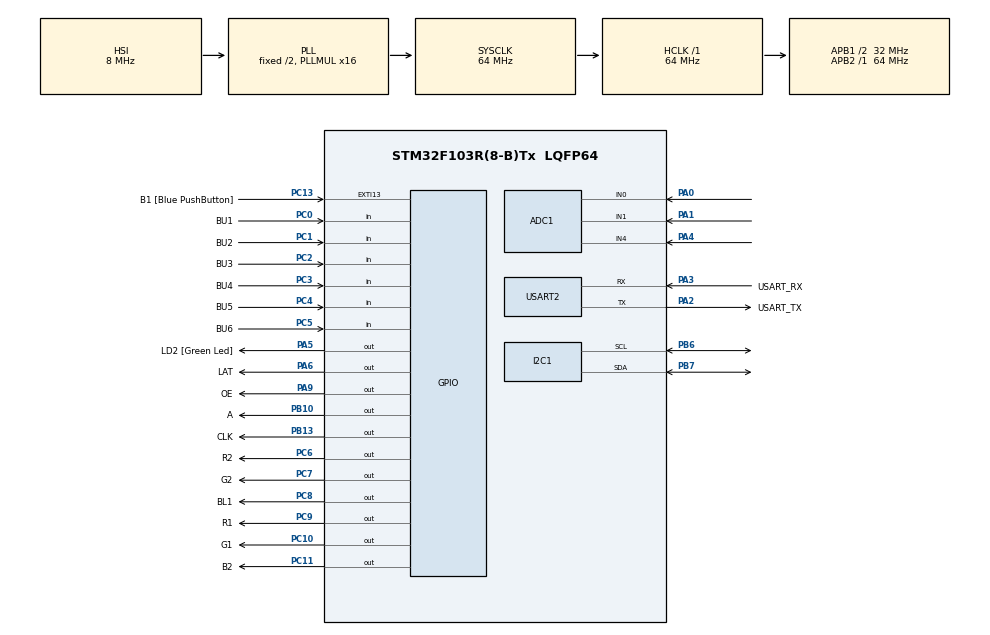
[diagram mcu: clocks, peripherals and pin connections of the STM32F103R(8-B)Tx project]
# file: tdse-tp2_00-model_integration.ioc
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ADC1.Channel-0\#ChannelRegularConversion=ADC_CHANNEL_0
ADC1.Channel-1\#ChannelRegularConversion=ADC_CHANNEL_1
ADC1.Channel-2\#ChannelRegularConversion=ADC_CHANNEL_4
ADC1.ContinuousConvMode=ENABLE
ADC1.NbrOfConversion=3
ADC1.NbrOfConversionFlag=1
ADC1.Rank-0\#ChannelRegularConversion=1
ADC1.Rank-1\#ChannelRegularConversion=2
ADC1.Rank-2\#ChannelRegularConversion=3
ADC1.SamplingTime-0\#ChannelRegularConversion=ADC_SAMPLETIME_239CYCLES_5
ADC1.SamplingTime-1\#ChannelRegularConversion=ADC_SAMPLETIME_239CYCLES_5
ADC1.SamplingTime-2\#ChannelRegularConversion=ADC_SAMPLETIME_239CYCLES_5
ADC1.master=1
Dma.ADC1.0.Direction=DMA_PERIPH_TO_MEMORY
Dma.ADC1.0.Instance=DMA1_Channel1
Dma.ADC1.0.MemDataAlignment=DMA_MDATAALIGN_HALFWORD
Dma.ADC1.0.MemInc=DMA_MINC_ENABLE
Dma.ADC1.0.Mode=DMA_CIRCULAR
Dma.ADC1.0.PeriphDataAlignment=DMA_PDATAALIGN_HALFWORD
Dma.ADC1.0.PeriphInc=DMA_PINC_DISABLE
Dma.ADC1.0.Priority=DMA_PRIORITY_LOW
Dma.Request0=ADC1
Mcu.Family=STM32F1
Mcu.Name=STM32F103R(8-B)Tx
Mcu.Package=LQFP64
NVIC.ADC1_2_IRQn=true\:0\:0\:false\:false\:true\:true\:true\:true
NVIC.DMA1_Channel1_IRQn=true\:0\:0\:false\:false\:true\:false\:true\:true
NVIC.EXTI15_10_IRQn=true\:0\:0\:false\:false\:true\:true\:true\:true
NVIC.PriorityGroup=NVIC_PRIORITYGROUP_4
PA0-WKUP.Signal=ADCx_IN0
PA1.Signal=ADCx_IN1
PA13.GPIO_Label=TMS
PA13.Mode=Serial_Wire
PA13.Signal=SYS_JTMS-SWDIO
PA14.GPIO_Label=TCK
PA14.Mode=Serial_Wire
PA14.Signal=SYS_JTCK-SWCLK
PA2.GPIO_Label=USART_TX
PA2.GPIO_Mode=GPIO_MODE_AF_PP
PA2.GPIO_PuPd=GPIO_NOPULL
PA2.GPIO_Speed=GPIO_SPEED_FREQ_LOW
PA2.Mode=Asynchronous
PA2.Signal=USART2_TX
PA3.GPIO_Label=USART_RX
PA3.GPIO_Mode=GPIO_MODE_AF_PP
PA3.GPIO_PuPd=GPIO_NOPULL
PA3.GPIO_Speed=GPIO_SPEED_FREQ_LOW
PA3.Mode=Asynchronous
PA3.Signal=USART2_RX
PA4.Signal=ADCx_IN4
PA5.GPIO_Label=LD2 [Green Led]
PA5.GPIO_ModeDefaultOutputPP=GPIO_MODE_OUTPUT_PP
PA5.GPIO_PuPd=GPIO_NOPULL
PA5.GPIO_Speed=GPIO_SPEED_FREQ_LOW
PA5.Signal=GPIO_Output
PA6.GPIO_Label=LAT
PA6.GPIO_Speed=GPIO_SPEED_FREQ_HIGH
PA6.Signal=GPIO_Output
PA9.GPIO_Label=OE
PA9.GPIO_Speed=GPIO_SPEED_FREQ_HIGH
PA9.Signal=GPIO_Output
PB10.GPIO_Label=A
PB10.GPIO_Speed=GPIO_SPEED_FREQ_HIGH
PB10.Signal=GPIO_Output
PB13.GPIO_Label=CLK
PB13.GPIO_Speed=GPIO_SPEED_FREQ_HIGH
PB13.Signal=GPIO_Output
PB3.GPIO_Label=SWO
PB3.Signal=SYS_JTDO-TRACESWO
PB6.Mode=I2C
PB6.Signal=I2C1_SCL
PB7.Mode=I2C
PB7.Signal=I2C1_SDA
PC0.GPIO_Label=BU1
PC0.GPIO_PuPd=GPIO_PULLUP
PC0.Signal=GPIO_Input
PC1.GPIO_Label=BU2
PC1.GPIO_PuPd=GPIO_PULLUP
PC1.Signal=GPIO_Input
PC10.GPIO_Label=G1
PC10.GPIO_Speed=GPIO_SPEED_FREQ_HIGH
PC10.Signal=GPIO_Output
PC11.GPIO_Label=B2
PC11.GPIO_Speed=GPIO_SPEED_FREQ_HIGH
PC11.Signal=GPIO_Output
PC13-TAMPER-RTC.GPIO_Label=B1 [Blue PushButton]
PC13-TAMPER-RTC.GPIO_PuPd=GPIO_NOPULL
PC13-TAMPER-RTC.Signal=GPXTI13
PC14-OSC32_IN.Mode=LSE-External-Oscillator
PC14-OSC32_IN.Signal=RCC_OSC32_IN
PC15-OSC32_OUT.Mode=LSE-External-Oscillator
PC15-OSC32_OUT.Signal=RCC_OSC32_OUT
PC2.GPIO_Label=BU3
PC2.GPIO_PuPd=GPIO_PULLUP
PC2.Signal=GPIO_Input
PC3.GPIO_Label=BU4
PC3.GPIO_PuPd=GPIO_PULLUP
PC3.Signal=GPIO_Input
PC4.GPIO_Label=BU5
PC4.GPIO_PuPd=GPIO_PULLUP
PC4.Signal=GPIO_Input
PC5.GPIO_Label=BU6
PC5.GPIO_PuPd=GPIO_PULLUP
PC5.Signal=GPIO_Input
PC6.GPIO_Label=R2
PC6.GPIO_Speed=GPIO_SPEED_FREQ_HIGH
PC6.Signal=GPIO_Output
PC7.GPIO_Label=G2
PC7.GPIO_Speed=GPIO_SPEED_FREQ_HIGH
PC7.Signal=GPIO_Output
PC8.GPIO_Label=BL1
PC8.GPIO_Speed=GPIO_SPEED_FREQ_HIGH
PC8.Signal=GPIO_Output
PC9.GPIO_Label=R1
PC9.GPIO_Speed=GPIO_SPEED_FREQ_HIGH
PC9.Signal=GPIO_Output
PD0-OSC_IN.Mode=HSE-External-Clock-Source
PD0-OSC_IN.Signal=RCC_OSC_IN
PD1-OSC_OUT.Mode=HSE-External-Clock-Source
PD1-OSC_OUT.Signal=RCC_OSC_OUT
ProjectManager.HeapSize=0x200
ProjectManager.StackSize=0x400
ProjectManager.TargetToolchain=STM32CubeIDE
RCC.ADCPresc=RCC_ADCPCLK2_DIV6
RCC.AHBFreq_Value=64000000
RCC.APB1CLKDivider=RCC_HCLK_DIV2
RCC.APB1Freq_Value=32000000
RCC.APB1TimFreq_Value=64000000
RCC.APB2Freq_Value=64000000
RCC.APB2TimFreq_Value=64000000
RCC.HCLKFreq_Value=64000000
RCC.PLLMUL=RCC_PLL_MUL16
RCC.RTCClockSelection=RCC_RTCCLKSOURCE_LSE
RCC.SYSCLKFreq_VALUE=64000000
RCC.SYSCLKSource=RCC_SYSCLKSOURCE_PLLCLK
RCC.USBFreq_Value=64000000
SH.ADCx_IN0.0=ADC1_IN0,IN0
SH.ADCx_IN1.0=ADC1_IN1,IN1
SH.ADCx_IN4.0=ADC1_IN4,IN4
USART2.VirtualMode=VM_ASYNC
board=NUCLEO-F103RB

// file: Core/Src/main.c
/* USER CODE BEGIN Header */
/**
  ******************************************************************************
  * @file           : main.c
  * @brief          : Main program body
  ******************************************************************************
  * @attention
  *
  * Copyright (c) 2026 STMicroelectronics.
  * All rights reserved.
  *
  * This software is licensed under terms that can be found in the LICENSE file
  * in the root directory of this software component.
  * If no LICENSE file comes with this software, it is provided AS-IS.
  *
  ******************************************************************************
  */
/* USER CODE END Header */
#include "main.h"

/* USER CODE BEGIN Includes */

/* Application includes */
#include "logger.h"
#include "app.h"
//#include "test.h"
/* USER CODE END Includes */

ADC_HandleTypeDef hadc1;
DMA_HandleTypeDef hdma_adc1;

I2C_HandleTypeDef hi2c1;

UART_HandleTypeDef huart2;

void SystemClock_Config(void);
static void MX_GPIO_Init(void);
static void MX_DMA_Init(void);
static void MX_USART2_UART_Init(void);
static void MX_ADC1_Init(void);
static void MX_I2C1_Init(void);

int main(void)
{

  /* MCU Configuration--------------------------------------------------------*/

  /* Reset of all peripherals, Initializes the Flash interface and the Systick. */
  HAL_Init();

  /* Configure the system clock */
  SystemClock_Config();

  /* USER CODE BEGIN SysInit */
  //DWT_Init();
  /* USER CODE END SysInit */

  /* Initialize all configured peripherals */
  MX_GPIO_Init();
  MX_DMA_Init();
  MX_USART2_UART_Init();
  MX_ADC1_Init();
  MX_I2C1_Init();
  /* USER CODE BEGIN 2 */

  /* Application Init */

  appInit();
 // testearWCET();//para testear wcet
  /* USER CODE END 2 */

  /* Infinite loop */
  while (1)
  {

    /* USER CODE BEGIN 3 */

    /* Application Update */

	  appUpdate();
  }
  /* USER CODE END 3 */
}

void SystemClock_Config(void)
{
  RCC_OscInitTypeDef RCC_OscInitStruct = {0};
  RCC_ClkInitTypeDef RCC_ClkInitStruct = {0};
  RCC_PeriphCLKInitTypeDef PeriphClkInit = {0};

  /** Initializes the RCC Oscillators according to the specified parameters
  * in the RCC_OscInitTypeDef structure.
  */
  RCC_OscInitStruct.OscillatorType = RCC_OSCILLATORTYPE_HSI;
  RCC_OscInitStruct.HSIState = RCC_HSI_ON;
  RCC_OscInitStruct.HSICalibrationValue = RCC_HSICALIBRATION_DEFAULT;
  RCC_OscInitStruct.PLL.PLLState = RCC_PLL_ON;
  RCC_OscInitStruct.PLL.PLLSource = RCC_PLLSOURCE_HSI_DIV2;
  RCC_OscInitStruct.PLL.PLLMUL = RCC_PLL_MUL16;
  if (HAL_RCC_OscConfig(&RCC_OscInitStruct) != HAL_OK)
  {
    Error_Handler();
  }

  /** Initializes the CPU, AHB and APB buses clocks
  */
  RCC_ClkInitStruct.ClockType = RCC_CLOCKTYPE_HCLK|RCC_CLOCKTYPE_SYSCLK
                              |RCC_CLOCKTYPE_PCLK1|RCC_CLOCKTYPE_PCLK2;
  RCC_ClkInitStruct.SYSCLKSource = RCC_SYSCLKSOURCE_PLLCLK;
  RCC_ClkInitStruct.AHBCLKDivider = RCC_SYSCLK_DIV1;
  RCC_ClkInitStruct.APB1CLKDivider = RCC_HCLK_DIV2;
  RCC_ClkInitStruct.APB2CLKDivider = RCC_HCLK_DIV1;

  if (HAL_RCC_ClockConfig(&RCC_ClkInitStruct, FLASH_LATENCY_2) != HAL_OK)
  {
    Error_Handler();
  }
  PeriphClkInit.PeriphClockSelection = RCC_PERIPHCLK_ADC;
  PeriphClkInit.AdcClockSelection = RCC_ADCPCLK2_DIV6;
  if (HAL_RCCEx_PeriphCLKConfig(&PeriphClkInit) != HAL_OK)
  {
    Error_Handler();
  }
}

static void MX_ADC1_Init(void)
{

  ADC_ChannelConfTypeDef sConfig = {0};

  /** Common config
  */
  hadc1.Instance = ADC1;
  hadc1.Init.ScanConvMode = ADC_SCAN_ENABLE;
  hadc1.Init.ContinuousConvMode = ENABLE;
  hadc1.Init.DiscontinuousConvMode = DISABLE;
  hadc1.Init.ExternalTrigConv = ADC_SOFTWARE_START;
  hadc1.Init.DataAlign = ADC_DATAALIGN_RIGHT;
  hadc1.Init.NbrOfConversion = 3;
  if (HAL_ADC_Init(&hadc1) != HAL_OK)
  {
    Error_Handler();
  }

  /** Configure Regular Channel
  */
  sConfig.Channel = ADC_CHANNEL_0;
  sConfig.Rank = ADC_REGULAR_RANK_1;
  sConfig.SamplingTime = ADC_SAMPLETIME_239CYCLES_5;
  if (HAL_ADC_ConfigChannel(&hadc1, &sConfig) != HAL_OK)
  {
    Error_Handler();
  }

  /** Configure Regular Channel
  */
  sConfig.Channel = ADC_CHANNEL_1;
  sConfig.Rank = ADC_REGULAR_RANK_2;
  if (HAL_ADC_ConfigChannel(&hadc1, &sConfig) != HAL_OK)
  {
    Error_Handler();
  }

  /** Configure Regular Channel
  */
  sConfig.Channel = ADC_CHANNEL_4;
  sConfig.Rank = ADC_REGULAR_RANK_3;
  if (HAL_ADC_ConfigChannel(&hadc1, &sConfig) != HAL_OK)
  {
    Error_Handler();
  }

}

static void MX_I2C1_Init(void)
{

  hi2c1.Instance = I2C1;
  hi2c1.Init.ClockSpeed = 100000;
  hi2c1.Init.DutyCycle = I2C_DUTYCYCLE_2;
  hi2c1.Init.OwnAddress1 = 0;
  hi2c1.Init.AddressingMode = I2C_ADDRESSINGMODE_7BIT;
  hi2c1.Init.DualAddressMode = I2C_DUALADDRESS_DISABLE;
  hi2c1.Init.OwnAddress2 = 0;
  hi2c1.Init.GeneralCallMode = I2C_GENERALCALL_DISABLE;
  hi2c1.Init.NoStretchMode = I2C_NOSTRETCH_DISABLE;
  if (HAL_I2C_Init(&hi2c1) != HAL_OK)
  {
    Error_Handler();
  }

}

static void MX_USART2_UART_Init(void)
{

  huart2.Instance = USART2;
  huart2.Init.BaudRate = 115200;
  huart2.Init.WordLength = UART_WORDLENGTH_8B;
  huart2.Init.StopBits = UART_STOPBITS_1;
  huart2.Init.Parity = UART_PARITY_NONE;
  huart2.Init.Mode = UART_MODE_TX_RX;
  huart2.Init.HwFlowCtl = UART_HWCONTROL_NONE;
  huart2.Init.OverSampling = UART_OVERSAMPLING_16;
  if (HAL_UART_Init(&huart2) != HAL_OK)
  {
    Error_Handler();
  }

}

static void MX_DMA_Init(void)
{

  /* DMA controller clock enable */
  __HAL_RCC_DMA1_CLK_ENABLE();

  /* DMA interrupt init */
  /* DMA1_Channel1_IRQn interrupt configuration */
  HAL_NVIC_SetPriority(DMA1_Channel1_IRQn, 0, 0);
  HAL_NVIC_EnableIRQ(DMA1_Channel1_IRQn);

}

static void MX_GPIO_Init(void)
{
  GPIO_InitTypeDef GPIO_InitStruct = {0};

  /* GPIO Ports Clock Enable */
  __HAL_RCC_GPIOC_CLK_ENABLE();
  __HAL_RCC_GPIOD_CLK_ENABLE();
  __HAL_RCC_GPIOA_CLK_ENABLE();
  __HAL_RCC_GPIOB_CLK_ENABLE();

  /*Configure GPIO pin Output Level */
  HAL_GPIO_WritePin(GPIOA, LD2_Pin|LAT_Pin|OE_Pin, GPIO_PIN_RESET);

  /*Configure GPIO pin Output Level */
  HAL_GPIO_WritePin(GPIOB, A_Pin|CLK_Pin, GPIO_PIN_RESET);

  /*Configure GPIO pin Output Level */
  HAL_GPIO_WritePin(GPIOC, R2_Pin|G2_Pin|BL1_Pin|R1_Pin
                          |G1_Pin|B2_Pin, GPIO_PIN_RESET);

  /*Configure GPIO pin : B1_Pin */
  GPIO_InitStruct.Pin = B1_Pin;
  GPIO_InitStruct.Mode = GPIO_MODE_IT_RISING;
  GPIO_InitStruct.Pull = GPIO_NOPULL;
  HAL_GPIO_Init(B1_GPIO_Port, &GPIO_InitStruct);

  /*Configure GPIO pins : BU1_Pin BU2_Pin BU3_Pin BU4_Pin
                           BU5_Pin BU6_Pin */
  GPIO_InitStruct.Pin = BU1_Pin|BU2_Pin|BU3_Pin|BU4_Pin
                          |BU5_Pin|BU6_Pin;
  GPIO_InitStruct.Mode = GPIO_MODE_INPUT;
  GPIO_InitStruct.Pull = GPIO_PULLUP;
  HAL_GPIO_Init(GPIOC, &GPIO_InitStruct);

  /*Configure GPIO pin : LD2_Pin */
  GPIO_InitStruct.Pin = LD2_Pin;
  GPIO_InitStruct.Mode = GPIO_MODE_OUTPUT_PP;
  GPIO_InitStruct.Pull = GPIO_NOPULL;
  GPIO_InitStruct.Speed = GPIO_SPEED_FREQ_LOW;
  HAL_GPIO_Init(LD2_GPIO_Port, &GPIO_InitStruct);

  /*Configure GPIO pins : LAT_Pin OE_Pin */
  GPIO_InitStruct.Pin = LAT_Pin|OE_Pin;
  GPIO_InitStruct.Mode = GPIO_MODE_OUTPUT_PP;
  GPIO_InitStruct.Pull = GPIO_NOPULL;
  GPIO_InitStruct.Speed = GPIO_SPEED_FREQ_HIGH;
  HAL_GPIO_Init(GPIOA, &GPIO_InitStruct);

  /*Configure GPIO pins : A_Pin CLK_Pin */
  GPIO_InitStruct.Pin = A_Pin|CLK_Pin;
  GPIO_InitStruct.Mode = GPIO_MODE_OUTPUT_PP;
  GPIO_InitStruct.Pull = GPIO_NOPULL;
  GPIO_InitStruct.Speed = GPIO_SPEED_FREQ_HIGH;
  HAL_GPIO_Init(GPIOB, &GPIO_InitStruct);

  /*Configure GPIO pins : R2_Pin G2_Pin BL1_Pin R1_Pin
                           G1_Pin B2_Pin */
  GPIO_InitStruct.Pin = R2_Pin|G2_Pin|BL1_Pin|R1_Pin
                          |G1_Pin|B2_Pin;
  GPIO_InitStruct.Mode = GPIO_MODE_OUTPUT_PP;
  GPIO_InitStruct.Pull = GPIO_NOPULL;
  GPIO_InitStruct.Speed = GPIO_SPEED_FREQ_HIGH;
  HAL_GPIO_Init(GPIOC, &GPIO_InitStruct);

  /* EXTI interrupt init*/
  HAL_NVIC_SetPriority(EXTI15_10_IRQn, 0, 0);
  HAL_NVIC_EnableIRQ(EXTI15_10_IRQn);

  /* USER CODE BEGIN MX_GPIO_Init_2 */
  GPIO_InitStruct.Pin = GPIO_PIN_0|GPIO_PIN_1|GPIO_PIN_4;
  GPIO_InitStruct.Mode = GPIO_MODE_ANALOG;
  HAL_GPIO_Init(GPIOA, &GPIO_InitStruct);
  /* USER CODE END MX_GPIO_Init_2 */
}

void Error_Handler(void)
{
  __disable_irq();
  while (1)
  {
  }
}
